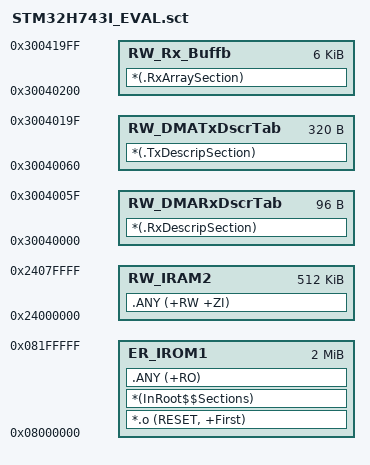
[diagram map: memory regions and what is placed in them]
; *************************************************************
; *** Scatter-Loading Description File generated by uVision ***
; *************************************************************

LR_IROM1 0x08000000 0x00200000  {    ; load region size_region
  ER_IROM1 0x08000000 0x00200000  {  ; load address = execution address
   *.o (RESET, +First)
   *(InRoot$$Sections)
   .ANY (+RO)
  }
  RW_IRAM2 0x24000000 0x00080000  {  ; RW data
   .ANY (+RW +ZI)
  }
  RW_DMARxDscrTab 0x30040000 0x60 {
  *(.RxDescripSection)
  }
  RW_DMATxDscrTab 0x30040060 0x140 {
  *(.TxDescripSection)
  }
  RW_Rx_Buffb 0x30040200 0x1800 {
  *(.RxArraySection)
  }
}




